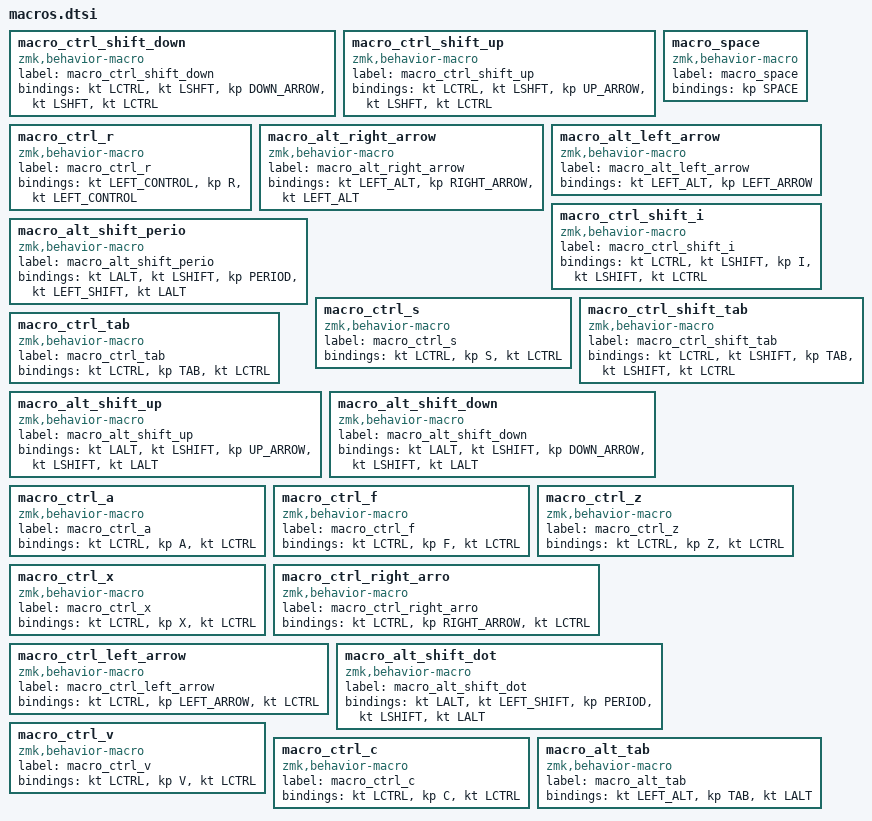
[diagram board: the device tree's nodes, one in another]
macro_ctrl_shift_down: macro_ctrl_shift_down{
compatible = "zmk,behavior-macro";
label = "macro_ctrl_shift_down";
#binding-cells = <0>;
bindings = <&kt LCTRL>, <&kt LSHFT>, <&kp DOWN_ARROW>, <&kt LSHFT>, <&kt LCTRL>;
};
macro_ctrl_shift_up: macro_ctrl_shift_up{
compatible = "zmk,behavior-macro";
label = "macro_ctrl_shift_up";
#binding-cells = <0>;
bindings = <&kt LCTRL>, <&kt LSHFT>, <&kp UP_ARROW>, <&kt LSHFT>, <&kt LCTRL>;
};
macro_space: macro_space{
compatible = "zmk,behavior-macro";
label = "macro_space";
#binding-cells = <0>;
bindings = <&kp SPACE>;
};
macro_ctrl_r: macro_ctrl_r{
compatible = "zmk,behavior-macro";
label = "macro_ctrl_r";
#binding-cells = <0>;
bindings = <&kt LEFT_CONTROL>, <&kp R>, <&kt LEFT_CONTROL>;
};
macro_alt_right_arrow: macro_alt_right_arrow{
compatible = "zmk,behavior-macro";
label = "macro_alt_right_arrow";
#binding-cells = <0>;
bindings = <&kt LEFT_ALT>, <&kp RIGHT_ARROW>, <&kt LEFT_ALT>;
};
macro_alt_left_arrow: macro_alt_left_arrow{
compatible = "zmk,behavior-macro";
label = "macro_alt_left_arrow";
#binding-cells = <0>;
bindings = <&kt LEFT_ALT>, <&kp LEFT_ARROW>;
};
macro_ctrl_shift_i: macro_ctrl_shift_i{
compatible = "zmk,behavior-macro";
label = "macro_ctrl_shift_i";
#binding-cells = <0>;
bindings = <&kt LCTRL>, <&kt LSHIFT>, <&kp I>, <&kt LSHIFT>, <&kt LCTRL>;
};
macro_alt_shift_perio: macro_alt_shift_perio{
compatible = "zmk,behavior-macro";
label = "macro_alt_shift_perio";
#binding-cells = <0>;
bindings = <&kt LALT>, <&kt LSHIFT>, <&kp PERIOD>, <&kt LEFT_SHIFT>, <&kt LALT>;
};
macro_ctrl_s: macro_ctrl_s{
compatible = "zmk,behavior-macro";
label = "macro_ctrl_s";
#binding-cells = <0>;
bindings = <&kt LCTRL>, <&kp S>, <&kt LCTRL>;
};
macro_ctrl_shift_tab: macro_ctrl_shift_tab{
compatible = "zmk,behavior-macro";
label = "macro_ctrl_shift_tab";
#binding-cells = <0>;
bindings = <&kt LCTRL>, <&kt LSHIFT>, <&kp TAB>, <&kt LSHIFT>, <&kt LCTRL>;
};
macro_ctrl_tab: macro_ctrl_tab{
compatible = "zmk,behavior-macro";
label = "macro_ctrl_tab";
#binding-cells = <0>;
bindings = <&kt LCTRL>, <&kp TAB>, <&kt LCTRL>;
};
macro_alt_shift_up: macro_alt_shift_up{
compatible = "zmk,behavior-macro";
label = "macro_alt_shift_up";
#binding-cells = <0>;
bindings = <&kt LALT>, <&kt LSHIFT>, <&kp UP_ARROW>, <&kt LSHIFT>, <&kt LALT>;
};
macro_alt_shift_down: macro_alt_shift_down{
compatible = "zmk,behavior-macro";
label = "macro_alt_shift_down";
#binding-cells = <0>;
bindings = <&kt LALT>, <&kt LSHIFT>, <&kp DOWN_ARROW>, <&kt LSHIFT>, <&kt LALT>;
};
macro_ctrl_a: macro_ctrl_a{
compatible = "zmk,behavior-macro";
label = "macro_ctrl_a";
#binding-cells = <0>;
bindings = <&kt LCTRL>, <&kp A>, <&kt LCTRL>;
};
macro_ctrl_f: macro_ctrl_f{
compatible = "zmk,behavior-macro";
label = "macro_ctrl_f";
#binding-cells = <0>;
bindings = <&kt LCTRL>, <&kp F>, <&kt LCTRL>;
};
macro_ctrl_z: macro_ctrl_z{
compatible = "zmk,behavior-macro";
label = "macro_ctrl_z";
#binding-cells = <0>;
bindings = <&kt LCTRL>, <&kp Z>, <&kt LCTRL>;
};
macro_ctrl_x: macro_ctrl_x{
compatible = "zmk,behavior-macro";
label = "macro_ctrl_x";
#binding-cells = <0>;
bindings = <&kt LCTRL>, <&kp X>, <&kt LCTRL>;
};
macro_ctrl_right_arro: macro_ctrl_right_arro{
compatible = "zmk,behavior-macro";
label = "macro_ctrl_right_arro";
#binding-cells = <0>;
bindings = <&kt LCTRL>, <&kp RIGHT_ARROW>, <&kt LCTRL>;
};
macro_ctrl_left_arrow: macro_ctrl_left_arrow{
compatible = "zmk,behavior-macro";
label = "macro_ctrl_left_arrow";
#binding-cells = <0>;
bindings = <&kt LCTRL>, <&kp LEFT_ARROW>, <&kt LCTRL>;
};
macro_alt_shift_dot: macro_alt_shift_dot{
compatible = "zmk,behavior-macro";
label = "macro_alt_shift_dot";
#binding-cells = <0>;
bindings = <&kt LALT>, <&kt LEFT_SHIFT>, <&kp PERIOD>, <&kt LSHIFT>, <&kt LALT>;
};
macro_ctrl_v: macro_ctrl_v{
compatible = "zmk,behavior-macro";
label = "macro_ctrl_v";
#binding-cells = <0>;
bindings = <&kt LCTRL>, <&kp V>, <&kt LCTRL>;
};
macro_ctrl_c: macro_ctrl_c{
compatible = "zmk,behavior-macro";
label = "macro_ctrl_c";
#binding-cells = <0>;
bindings = <&kt LCTRL>, <&kp C>, <&kt LCTRL>;
};
macro_alt_tab: macro_alt_tab{
compatible = "zmk,behavior-macro";
label = "macro_alt_tab";
#binding-cells = <0>;
bindings = <&kt LEFT_ALT>, <&kp TAB>, <&kt LALT>;
};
